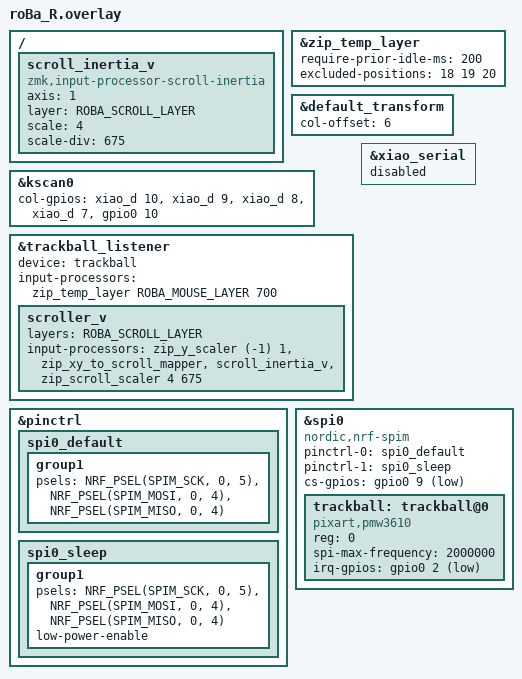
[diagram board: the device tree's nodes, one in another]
#include "roBa.dtsi"
#include <input/processors.dtsi>

// Existing keymap layer indices. Change these only when redesigning layers.
#define ROBA_MOUSE_LAYER 4
#define ROBA_SCROLL_LAYER 5

&zip_temp_layer {
    require-prior-idle-ms = <200>;
    // J, K and L are the existing mouse button positions on layer 4.
    excluded-positions = <18 19 20>;
};

&default_transform {
    col-offset = <6>;
};

&kscan0 {
        col-gpios
            = <&xiao_d 10 GPIO_ACTIVE_HIGH>
            , <&xiao_d 9 GPIO_ACTIVE_HIGH>
            , <&xiao_d 8 GPIO_ACTIVE_HIGH>
            , <&xiao_d 7 GPIO_ACTIVE_HIGH>
            , <&gpio0 10 GPIO_ACTIVE_HIGH>
            ;
};

/ {
    scroll_inertia_v: scroll_inertia_v {
        compatible = "zmk,input-processor-scroll-inertia";
        #input-processor-cells = <0>;
        axis = <1>;
        layer = <ROBA_SCROLL_LAYER>;
        scale = <4>;
        scale-div = <675>;
    };
};

&trackball_listener {
    status = "okay";
    device = <&trackball>;
    input-processors = <&zip_temp_layer ROBA_MOUSE_LAYER 700>;

    scroller_v {
        layers = <ROBA_SCROLL_LAYER>;
        input-processors = <
            &zip_y_scaler (-1) 1
            &zip_xy_to_scroll_mapper
            &scroll_inertia_v
            &zip_scroll_scaler 4 675
        >;
    };
};

&pinctrl {
    spi0_default: spi0_default {
        group1 {
            psels = <NRF_PSEL(SPIM_SCK, 0, 5)>,
                <NRF_PSEL(SPIM_MOSI, 0, 4)>,
                <NRF_PSEL(SPIM_MISO, 0, 4)>;
        };
    };

    spi0_sleep: spi0_sleep {
        group1 {
            psels = <NRF_PSEL(SPIM_SCK, 0, 5)>,
                <NRF_PSEL(SPIM_MOSI, 0, 4)>,
                <NRF_PSEL(SPIM_MISO, 0, 4)>;
            low-power-enable;
        };
    };
};

&xiao_serial { status = "disabled"; };

&spi0 {
    status = "okay";
    compatible = "nordic,nrf-spim";
    pinctrl-0 = <&spi0_default>;
    pinctrl-1 = <&spi0_sleep>;
    pinctrl-names = "default", "sleep";
    cs-gpios = <&gpio0 9 GPIO_ACTIVE_LOW>;

    trackball: trackball@0 {
        status = "okay";
        compatible = "pixart,pmw3610";
        reg = <0>;
        spi-max-frequency = <2000000>;
        irq-gpios = <&gpio0 2 (GPIO_ACTIVE_LOW | GPIO_PULL_UP)>;
    };
};
